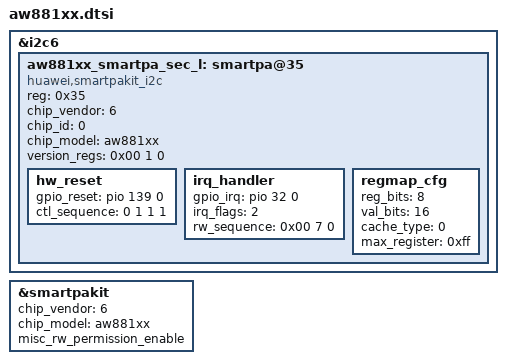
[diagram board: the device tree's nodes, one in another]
&i2c6 {
	aw881xx_smartpa_sec_l:smartpa@35 {
		compatible = "huawei,smartpakit_i2c";
		reg = <0x35>;
		/* 0 MAXIM, 1 NXP, 2 TI, 3 CS, 4 CUST, 5 RT, 6 AWINIC */
		chip_vendor = <6>;
		/* refer to smartpakit.out_device prop */
		chip_id = <0>;
		chip_model = "aw881xx";
		status = "ok";

		/* reg_ctl node: a node contains three data<addr value ctl_type>
		 * ctl_type: 0 read reg(default), 1 write reg, 2 only time delay
		 * value:
		 *     read:  reg number(num >= 1)
		 *     write: reg value
		 *     delay: time delay
		 * time delay unit: msecs */
		version_regs = <0x00 1 0>;
		hw_reset {
			gpio_reset = <&pio 139 0>;
			ctl_sequence = <0 1 1 1>;
		};
		irq_handler {
			gpio_irq = <&pio 32 0>;
			/* 0x0 IRQF_TRIGGER_NONE, 0x1 IRQF_TRIGGER_RISING, 0x2 IRQF_TRIGGER_FALLING, 0x4 IRQF_TRIGGER_HIGH, 0x8 IRQF_TRIGGER_LOW */
			irq_flags = <2>;
			rw_sequence = <0x00 7 0>;
		};
		regmap_cfg {
			reg_bits = <8>;
			val_bits = <16>;
			/* 0 REGCACHE_NONE, 1 REGCACHE_RBTREE, 2 REGCACHE_COMPRESSED, 3 REGCACHE_FLAT */
			cache_type = <0>;
			max_register = <0xff>;
		};
	};
};

&smartpakit {
	chip_vendor = <6>;
	chip_model = "aw881xx";
	misc_rw_permission_enable;
};
